# APP_RCM register map
Vendor: Texas Instruments
Peripheral module from a debugger description file (folder xwrl64xx).
Registers are 32-bit, read-write, no defined reset value unless marked. A register's access mark holds for its fields unless they carry their own. Offsets are as the file gives them; lines under a group give offsets from that group; [hi:lo] are bit positions; {n}, {i} and the like mark numbered series; 'fields as' and 'values as' point back to an identical list; <NAME> marks a mode.

## APP_RCM
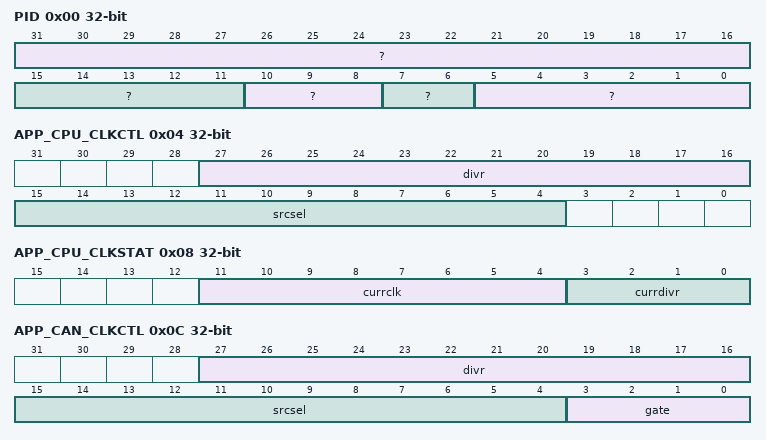
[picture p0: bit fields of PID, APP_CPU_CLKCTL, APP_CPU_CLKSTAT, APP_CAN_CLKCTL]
0x00 PID ro
  [31:16] ?, [15:11] ?, [10:8] ?, [7:6] ?, [5:0] ?
0x04 APP_CPU_CLKCTL
  [27:16] divr — Divide value 0x0 : div1 0x1 : div2 0x2 : div3 . . 0xF = div16 Data should be loaded as multibit. For example: if divider value of '0x8' should be selected then '0x888' should be configured to the register.
  [15:4] srcsel — Select the source clock: 0x0 : OSC_CLK 0x1 : SLOW_CLK 0x2 : MDLL_CLK 0x3 : FAST_CLK 0x4 : SLOW_CLK 0x5 : SLOW_CLK 0x6 : SLOW_CLK 0x7 : SLOW_CLK For other values if the lower 3 bits matches with above, corresponding clock is selected. Data should be loaded as multibit. For example: if Clock source 0x5 should be selected then 0x555 should be configured to the register.
0x08 APP_CPU_CLKSTAT ro
  [11:4] currclk — Current Clock selected by GCM Clock Mux 0x1 : XTALCLK 0x2 : XTALCLKX2 0x4 : MDLL 0x8 : APLL/DPLL 0x10 : RCCLK
  [3:0] currdivr — Gives the current divr setting used by the clock divider.
0x0C APP_CAN_CLKCTL
  [27:16] divr — Divide value 0x0 : div1 0x1 : div2 0x2 : div3 . . 0xF = div16 Data should be loaded as multibit. For example: if divider value of '0x8' should be selected then '0x888' should be configured to the register.
  [15:4] srcsel — 0x0 : OSC_CLK 0x1 : OSC_CLKX2 0x2 : MDLL_CLK 0x3 : FAST_CLK 0x4 : SLOW_CLK 0x5 : SLOW_CLK 0x6 : SLOW_CLK 0x7 : SLOW_CLKFor other values if the lower 3 bits matches with above, corresponding clock is selected. Data should be loaded as multibit. For example: if Clock source 0x5 should be selected then 0x555 should be configured to the register.
  [3:0] gate — 0x0 : Enable the Clock 0x7 : Gate the clock
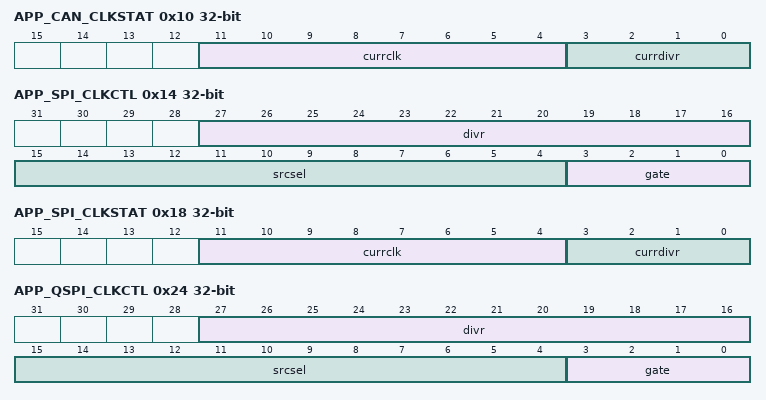
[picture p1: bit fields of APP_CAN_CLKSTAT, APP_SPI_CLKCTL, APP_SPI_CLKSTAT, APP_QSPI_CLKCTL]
0x10 APP_CAN_CLKSTAT ro
  fields as APP_CPU_CLKSTAT
0x14 APP_SPI_CLKCTL
  [27:16] divr — Divide value 0x0 : div1 0x1 : div2 0x2 : div3 . . 0xF = div16 Data should be loaded as multibit. For example: if divider value of '0x8' should be selected then '0x888' should be configured to the register.
  [15:4] srcsel — 0x0 : OSC_CLK 0x1 : OSC_CLKX2 0x2 : MDLL_CLK 0x3 : FAST_CLK 0x4 : SLOW_CLK 0x5 : SLOW_CLK 0x6 : SLOW_CLK 0x7 : SLOW_CLK For other values if the lower 3 bits matches with above, corresponding clock is selected. Data should be loaded as multibit. For example: if Clock source 0x5 should be selected then 0x555 should be configured to the register.
  [3:0] gate — 0x0 : Enable the Clock 0x7 : Gate the clock
0x18 APP_SPI_CLKSTAT ro
  fields as APP_CPU_CLKSTAT
0x1C APP_SPI_BUSIF_CLKCTL
  [11:0] divr — Divide value 0x0 : div1 0x1 : div2 0x2 : div3 . . 0xF = div16 Data should be loaded as multibit. For example: if divider value of '0x8' should be selected then '0x888' should be configured to the register.
0x20 APP_SPI_BUSIF_CLKSTAT ro
  [3:0] currdivr — Gives the current divr setting used by the clock divider.
0x24 APP_QSPI_CLKCTL
  fields as APP_SPI_CLKCTL
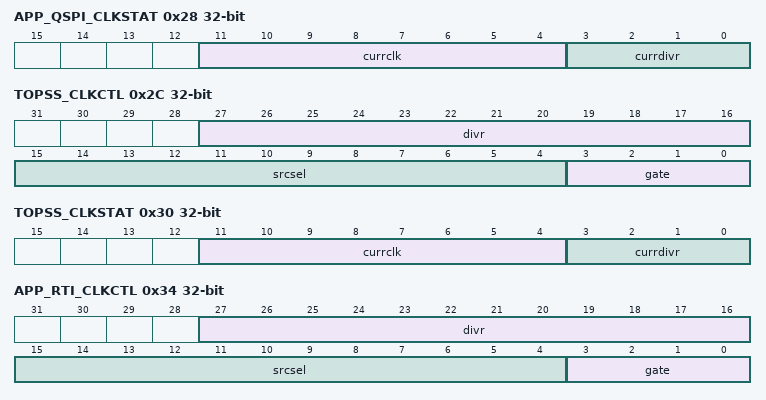
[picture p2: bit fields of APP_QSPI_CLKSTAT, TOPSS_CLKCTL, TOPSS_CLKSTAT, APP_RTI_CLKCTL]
0x28 APP_QSPI_CLKSTAT ro
  fields as APP_CPU_CLKSTAT
0x2C TOPSS_CLKCTL
  [27:16] divr — Divide value 0x0 : div1 0x1 : div2 0x2 : div3 . . 0xF = div16 Data should be loaded as multibit. For example: if divider value of '0x8' should be selected then '0x888' should be configured to the register.
  [15:4] srcsel — 0x0 : OSC_CLK 0x1 : SLOW_CLK 0x2 : MDLL 0x3 : FAST_CLK 0x4 : SLOW_CLK For other values if the lower 3 bits matches with above, corresponding clock is selected. Data should be loaded as multibit. For example: if Clock source 0x5 should be selected then 0x555 should be configured to the register.
  [3:0] gate — 0x0 : Enable the Clock 0x7 : Gate the clock
0x30 TOPSS_CLKSTAT ro
  fields as APP_CPU_CLKSTAT
0x34 APP_RTI_CLKCTL
  [27:16] divr — Divide value 0x0 : div1 0x1 : div2 0x2 : div3 . . 0xF = div16 Data should be loaded as multibit. For example: if divider value of '0x8' should be selected then '0x888' should be configured to the register.
  [15:4] srcsel — 0x0 : OSC_CLK 0x1 : XREF_IN 0x2 : OSC_CLK (Ungated OSC_CLK for RTI in Sleep mode) 0x3 : SLOW_CLK 0x4 : SLOW_CLK 0x5 : SLOW_CLK 0x6 : SLOW_CLK 0x7 : SLOW_CLK For other values if the lower 3 bits matches with above, corresponding clock is selected. Data should be loaded as multibit. For example: if Clock source 0x5 should be selected then 0x555 should be configured to the register.
  [3:0] gate — 0x0 : Enable the Clock 0x7 : Gate the clock
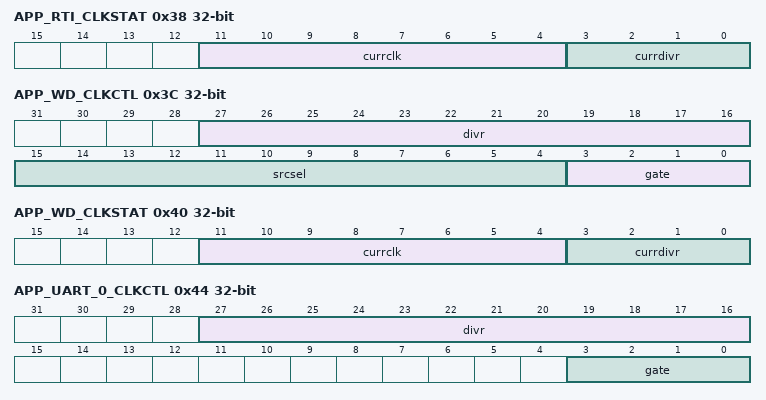
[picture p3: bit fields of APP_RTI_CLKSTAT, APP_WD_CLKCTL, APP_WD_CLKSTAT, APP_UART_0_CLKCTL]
0x38 APP_RTI_CLKSTAT ro
  fields as APP_CPU_CLKSTAT
0x3C APP_WD_CLKCTL
  [27:16] divr — Divide value 0x0 : div1 0x1 : div2 0x2 : div3 . . 0xF = div16 Data should be loaded as multibit. For example: if divider value of '0x8' should be selected then '0x888' should be configured to the register.
  [15:4] srcsel — 0x0 : OSC_CLK 0x1 : XREF_IN 0x2 : OSC_CLK 0x3 : SLOW_CLK 0x4 : SLOW_CLK 0x5 : SLOW_CLK 0x6 : SLOW_CLK 0x7 : SLOW_CLK For other values if the lower 3 bits matches with above, corresponding clock is selected. Data should be loaded as multibit. For example: if Clock source 0x5 should be selected then 0x555 should be configured to the register.
  [3:0] gate — 0x0 : Enable the Clock 0x7 : Gate the clock
0x40 APP_WD_CLKSTAT ro
  fields as APP_CPU_CLKSTAT
0x44 APP_UART_0_CLKCTL
  [27:16] divr — Divide value 0x0 : div1 0x1 : div2 0x2 : div3 . . 0xF = div16 Data should be loaded as multibit. For example: if divider value of '0x8' should be selected then '0x888' should be configured to the register.
  [3:0] gate — 0x0 : Enable the Clock 0x7 : Gate the clock
0x48 APP_UART_0_CLKSTAT ro
  fields as APP_SPI_BUSIF_CLKSTAT
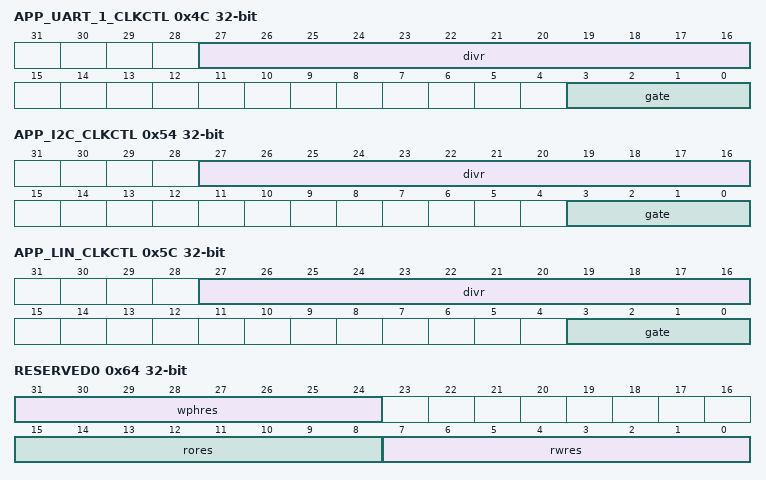
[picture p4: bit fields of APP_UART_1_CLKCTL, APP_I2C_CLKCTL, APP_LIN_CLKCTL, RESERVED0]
0x4C APP_UART_1_CLKCTL
  fields as APP_UART_0_CLKCTL
0x50 APP_UART_1_CLKSTAT ro
  fields as APP_SPI_BUSIF_CLKSTAT
0x54 APP_I2C_CLKCTL
  fields as APP_UART_0_CLKCTL
0x58 APP_I2C_CLKSTAT ro
  fields as APP_SPI_BUSIF_CLKSTAT
0x5C APP_LIN_CLKCTL
  fields as APP_UART_0_CLKCTL
0x60 APP_LIN_CLKSTAT ro
  fields as APP_SPI_BUSIF_CLKSTAT
0x64 RESERVED0 access per field
  [31:24] wphres rw — Reserved
  [15:8] rores ro — Reserved
  [7:0] rwres rw — Bit 2:0 - Software reset for hwass cba3to2 and m64top32 bridge instances in appss. (reset value - 0) Bit 5:3 - Software reset for fecss p2p async bridge instance in appss. (reset value - 0) 0x0 : Release the reset 0x7 : Assert the reset Bit 31:6 - Reserved
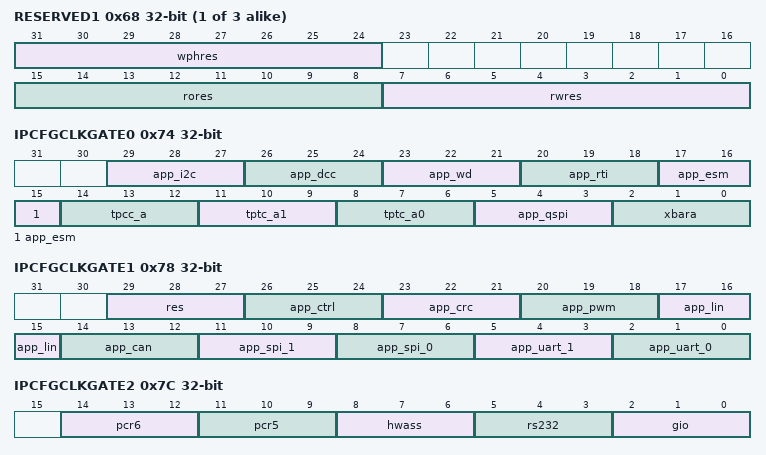
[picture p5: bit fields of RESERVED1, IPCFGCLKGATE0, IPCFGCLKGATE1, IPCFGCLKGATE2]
{0x64+4i} RESERVED{i} access per field (i=1..3)
  [31:24] wphres rw — Reserved
  [15:8] rores ro — Reserved
  [7:0] rwres rw — Reserved
0x74 IPCFGCLKGATE0
  [29:27] app_i2c — 0x0 : Enable the Clock 0x7 : Gate the clock
  [26:24] app_dcc — 0x0 : Enable the Clock 0x7 : Gate the clock
  [23:21] app_wd — 0x0 : Enable the Clock 0x7 : Gate the clock
  [20:18] app_rti — 0x0 : Enable the Clock 0x7 : Gate the clock
  [17:15] app_esm — 0x0 : Enable the Clock 0x7 : Gate the clock
  [14:12] tpcc_a — 0x0 : Enable the Clock 0x7 : Gate the clock
  [11:9] tptc_a1 — 0x0 : Enable the Clock 0x7 : Gate the clock
  [8:6] tptc_a0 — 0x0 : Enable the Clock 0x7 : Gate the clock
  [5:3] app_qspi — 0x0 : Enable the Clock 0x7 : Gate the clock
  [2:0] xbara — Reserved Setting this bit does not cause any affect to any logic
0x78 IPCFGCLKGATE1
  [29:27] res — 0x0 : Enable the Clock 0x7 : Gate the clock
  [26:24] app_ctrl — 0x0 : Enable the Clock 0x7 : Gate the clock
  [23:21] app_crc — 0x0 : Enable the Clock 0x7 : Gate the clock
  [20:18] app_pwm — 0x0 : Enable the Clock 0x7 : Gate the clock
  [17:15] app_lin — 0x0 : Enable the Clock 0x7 : Gate the clock
  [14:12] app_can — 0x0 : Enable the Clock 0x7 : Gate the clock
  [11:9] app_spi_1 — 0x0 : Enable the Clock 0x7 : Gate the clock
  [8:6] app_spi_0 — 0x0 : Enable the Clock 0x7 : Gate the clock
  [5:3] app_uart_1 — 0x0 : Enable the Clock 0x7 : Gate the clock
  [2:0] app_uart_0 — 0x0 : Enable the Clock 0x7 : Gate the clock
0x7C IPCFGCLKGATE2
  [14:12] pcr6 — 0x0 : Enable the Clock 0x7 : Gate the clock
  [11:9] pcr5 — 0x0 : Enable the Clock 0x7 : Gate the clock
  [8:6] hwass — 0x0 : Enable the Clock 0x7 : Gate the clock
  [5:3] rs232 — 0x0 : Enable the Clock 0x7 : Gate the clock
  [2:0] gio — 0x0 : Enable the Clock 0x7 : Gate the clock
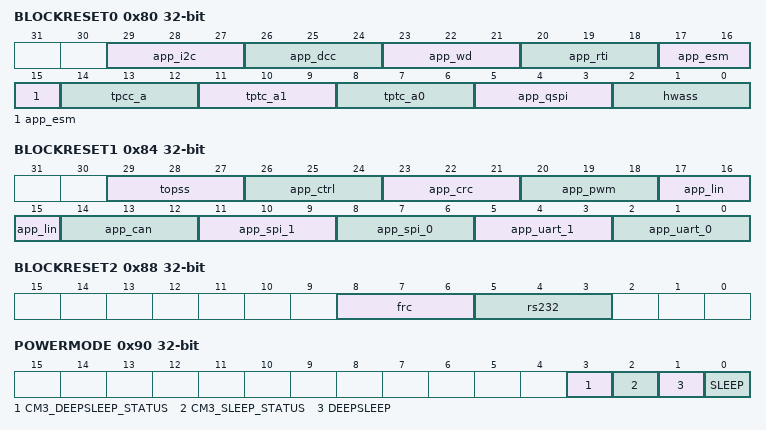
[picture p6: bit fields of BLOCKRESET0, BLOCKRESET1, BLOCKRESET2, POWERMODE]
0x80 BLOCKRESET0
  [29:27] app_i2c — 0x0 : Release the reset 0x7 : Assert the reset
  [26:24] app_dcc — 0x0 : Release the reset 0x7 : Assert the reset
  [23:21] app_wd — 0x0 : Release the reset 0x7 : Assert the reset
  [20:18] app_rti — 0x0 : Release the reset 0x7 : Assert the reset
  [17:15] app_esm — 0x0 : Release the reset 0x7 : Assert the reset
  [14:12] tpcc_a — 0x0 : Release the reset 0x7 : Assert the reset
  [11:9] tptc_a1 — 0x0 : Release the reset 0x7 : Assert the reset
  [8:6] tptc_a0 — 0x0 : Release the reset 0x7 : Assert the reset
  [5:3] app_qspi — 0x0 : Release the reset 0x7 : Assert the reset
  [2:0] hwass — 0x0 : Release the reset 0x7 : Assert the reset
0x84 BLOCKRESET1
  [29:27] topss — 0x0 : Release the reset 0x7 : Assert the reset
  [26:24] app_ctrl — 0x0 : Release the reset 0x7 : Assert the reset
  [23:21] app_crc — 0x0 : Release the reset 0x7 : Assert the reset
  [20:18] app_pwm — 0x0 : Release the reset 0x7 : Assert the reset
  [17:15] app_lin — 0x0 : Release the reset 0x7 : Assert the reset
  [14:12] app_can — 0x0 : Release the reset 0x7 : Assert the reset
  [11:9] app_spi_1 — 0x0 : Release the reset 0x7 : Assert the reset
  [8:6] app_spi_0 — 0x0 : Release the reset 0x7 : Assert the reset
  [5:3] app_uart_1 — 0x0 : Release the reset 0x7 : Assert the reset
  [2:0] app_uart_0 — 0x0 : Release the reset 0x7 : Assert the reset
0x88 BLOCKRESET2
  [8:6] frc — 0x0 : Release the reset 0x7 : Assert the reset
  [5:3] rs232 — 0x0 : Release the reset 0x7 : Assert the reset
0x8C PLATFORM_SIGNATURE
  [31:0] signature — Platform signature to identify the platform
0x90 POWERMODE access per field
  [3] CM3_DEEPSLEEP_STATUS ro — CM3 Core Deep Sleep Status
  [2] CM3_SLEEP_STATUS ro — CM3 Core Sleep Status
  [1] DEEPSLEEP rw — 0x0 : CM4 CORE DEEP SLEEP 0x1 : DEVICE DEEP SLEEP
  [0] SLEEP rw — 0x0 : CM4 CORE SLEEP 0x1 : DEVICE SLEEP
0x94 RST_WFICHECK
  [2:0] cpu — Writing '000' will disable check for WFI before local reset assertion of app cpu
0x98 RST_ASSERTDLY
  [7:0] common — Value decides number of cycles reset should be asserted for cpu
0x9C RST2ASSERTDLY
  [15:8] cpu — Value decides number of cycles to be held before asserting reset for app cpu
0xA0 RST_FSM_TRIG
  [2:0] cpu — FSM Reset Trigger
0xA4 RST_CAUSE ro
  [7:0] common — Reset cause register for APP CPU 0x00 - All cleared 0x01 - Power On Reset (PoR) 0x02 - Subsystem Reset (Combination of Warm Reset initiated from PRCM using LPRADAR:TOP_PRCM:RST_APP_PD_SOFT_RESET and PoR reset) 0x04 - STC RESET 0x08 - Reserved 0x10 - CPU Only Reset triggered by writing to LPRADAR:APP_RCM:RST_FSM_TRIG<RST_FSM_TRIG_CPU> (self triggered CPU reset during MEMSWAP/ECLIPSE mode to wait for WFI to assert the reset to CPU) 0x20 - Core Reset initiated from PRCM using LPRADAR:TOP_PRCM:RST_SOFT_APP_CORE_SYSRESET_REQ (reset CPU unconditionally - by debugger) or LPRADAR:TOP_PRCM:APP_CORE_SYSRESET_PARAM_WAKEUP_OUT_STATE 0x40 - Reserved
0xA8 RST_CAUSE_CLR
  [2:0] cpu — Writing '111' will clear the RST_CAUSE register
0xAC XTALCLK_CLK_GATE
  [2:0] XTALCLK_CLK_GATE — RESERVED
0xB0 XTALCLKX2_CLK_GATE
  [2:0] XTALCLKX2_CLK_GATE — Writing 3'b111 will gate the XTALX2 clock.Writing 3'b000 will ungate the clock.
0xB4 APLLDIV2_CLK_GATE
  [2:0] APLLDIV2_CLK_GATE — Writing 3'b111 will gate the APLL/2clock to EDCC.Writing 3'b000 will ungate the clock.
0xB8 DFT_APPSS_LSTC_CLK_GATE
  [2:0] DFT_APPSS_LSTC_CLK_GATE — Writing 3'b111 will gate the clock to LSTC.Writing 3'b000 will ungate the clock.
0xBC DFT_APPSS_LSTC_VBUSP_CLK_GATE
  [2:0] enable — 3'b000 : Gate clock to LSTC VBUSP 3'b111 : Ungate Clock to LSTC VBUSP
0xC0 APP_ROM_CLOCK_GATE
  [2:0] enable — 3'b000 : Ungate clock to APP ROM 3'b111 : Gate Clock to APP ROM
0xC4 APP_RAM1_CLOCK_GATE
  [2:0] enable — 3'b000 : Ungate clock to APP RAM1 3'b111 : Gate Clock to APP_RAM1
0xC8 APP_RAM2_CLOCK_GATE
  [2:0] enable — 3'b000 : Ungate clock to APP RAM2 3'b111 : Gate Clock to APP RAM2
0xCC APP_RAM3_CLOCK_GATE
  [2:0] enable — 3'b000 : Ungate clock to APP RAM3 3'b111 : Gate Clock to APP RAM3
0xD0 CFG_XBARA_DYNAMIC_CG
  [2:0] enable — Enable APPSS crossbar dynamic clock gating. 1 - Dynamic clock gating feature is enabled. When the feature is enabed, the CM4 should monitor for any possible pending transactions from various masters like DMA/NWA and if no transaction is expected to be iniated by the masters, the CM4 executes WFI. On ssertion of WFI signal, the clock to crossbar is gated. The clock is automatically ungated under two conditions (i) when the WFI signal is deasserted by any interrupted (ii) when any of the APPSS TPCC triggers are asserted. Instead of WFI, cfg_xbara_set_dynamic_cg also can be used to start the clock gating. 0 - Dynamic clock gating feature is disabled. The clock to APPSS crossbar is not gated dynamically. The clock to APPSS crossbar is gated/ungated as per device ice level power states.
0xD4 CFG_TPTC1_DYNAMIC_CG
  [2:0] enable — Enable APPSS TPTC1 crossbar dynamic clock gating. 1 - Dynamic clock gating feature is enabled. Same behaviour as cfg_xbara_dynamic_cg_en - for both entry to clock gating and exit from clock gating. WFI or cfg_tptc1_set_dynamic_cg 0 - Dynamic clock gating feature is disabled. The clock to APPSS TPTC1 crossbar is not gated dynamically. The clock to APPSS TPTC1 crossbar is gated/ungated as per device ice level power states.
0xD8 CFG_TPTC2_DYNAMIC_CG
  [2:0] enable — Enable APPSS TPTC2 crossbar dynamic clock gating. 1 - Dynamic clock gating feature is enabled. Same behaviour as cfg_xbara_dynamic_cg_en - for both entry to clock gating and exit from clock gating. WFI or cfg_tptc2_set_dynamic_cg 0 - Dynamic clock gating feature is disabled. The clock to APPSS TPTC2 crossbar is not gated dynamically. The clock to APPSS TPTC2 crossbar is gated/ungated as per device ice level power states
0xDC CFG_XBARA_SET_DYNAMIC_CG
  [0] set — Start APPSS crossbar dynamic clock gating. This is used instead of WFI. 1 - Start the clock gating. In order to start again, write 0 followed by 1. Rise edge is detected internally, to start the clock gating. 0 - Clock is ungated. Fall edge is detected internally to ungate the clock.
0xE0 CFG_TPTC1_SET_DYNAMIC_CG
  [0] set — Start APPSS tptc1 dynamic clock gating. This is used instead of WFI. 1 - Start the clock gating. In order to start again, write 0 followed by 1. Rise edge is detected internally, to start the clock gating. 0 - Clock is ungated. Fall edge is detected internally to ungate the clock.
0xE4 CFG_TPTC2_SET_DYNAMIC_CG
  [0] set — Start APPSS tptc2 dynamic clock gating. This is used instead of WFI. 1 - Start the clock gating. In order to start again, write 0 followed by 1. Rise edge is detected internally, to start the clock gating. 0 - Clock is ungated. Fall edge is detected internally to ungate the clock.
0xE8 CM4_FORCE_HCLK_GATE
  [2:0] enable — 3'b000 - CM4 HCLK is ungated 3'b111 - CM4 HCLK is gated
0xEC LIN_SCI_DIV
  [7:0] val — ICG Based Divider for LIN
0xF0 APP_LSTC_EN
  [0] enable — Enable vbusp_req and clk_en for app lstc
0x1008 LOCK0_KICK0 — - KICK0 component
  [31:0] ?
0x100C LOCK0_KICK1 — - KICK1 component
  [31:0] ?
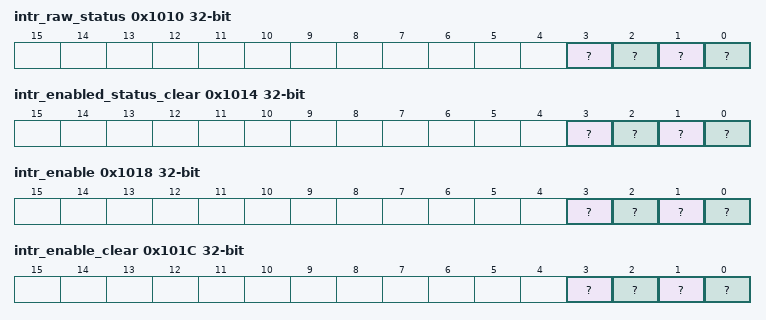
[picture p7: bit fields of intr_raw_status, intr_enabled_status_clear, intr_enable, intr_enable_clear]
0x1010 intr_raw_status — Interrupt Raw Status/Set Register
  [3] ? — Proxy0 access violation error. Raw status is read. Write a 1 to set the status. Writing a 0 has no effect.
  [2] ? — Kick access violation error. Raw status is read. Write a 1 to set the status. Writing a 0 has no effect.
  [1] ? — Addressing violation error. Raw status is read. Write a 1 to set the status. Writing a 0 has no effect.
  [0] ? — Protection violation error. Raw status is read. Write a 1 to set the status. Writing a 0 has no effect.
0x1014 intr_enabled_status_clear — Interrupt Enabled Status/Clear register
  [3] ? — Proxy0 access violation error. Enabled status is read. Write a 1 to clear the status. Writing a 0 has no effect.
  [2] ? — Kick access violation error. Enabled status is read. Write a 1 to clear the status. Writing a 0 has no effect.
  [1] ? — Addressing violation error. Enabled status is read. Write a 1 to clear the status. Writing a 0 has no effect.
  [0] ? — Protection violation error. Enabled status is read. Write a 1 to clear the status. Writing a 0 has no effect.
0x1018 intr_enable — Interrupt Enable register
  [3] ? — Proxy0 access violation error enable. Write a 1 to set the enable. Writing a 0 has no effect.
  [2] ? — Kick access violation error enable. Write a 1 to set the enable. Writing a 0 has no effect.
  [1] ? — Addressing violation error enable. Write a 1 to set the enable. Writing a 0 has no effect.
  [0] ? — Protection violation error enable. Write a 1 to set the enable. Writing a 0 has no effect.
0x101C intr_enable_clear — Interrupt Enable Clear register
  [3] ? — Proxy0 access violation error enable clear. Write a 1 to clear the enable. Writing a 0 has no effect.
  [2] ? — Kick access violation error enable clear. Write a 1 to clear the enable. Writing a 0 has no effect.
  [1] ? — Addressing violation error enable clear. Write a 1 to clear the enable. Writing a 0 has no effect.
  [0] ? — Protection violation error enable clear. Write a 1 to clear the enable. Writing a 0 has no effect.
0x1020 eoi
  [7:0] ? — EOI vector value. Write this with interrupt distribution value in the chip.
0x1024 fault_address ro
  [31:0] ? — Fault Address.
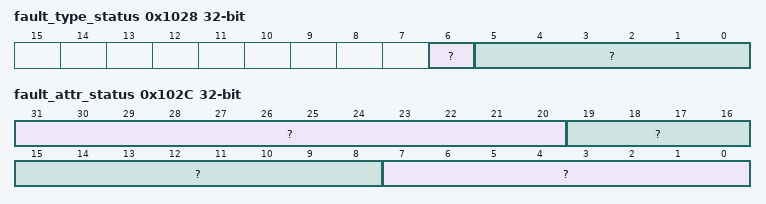
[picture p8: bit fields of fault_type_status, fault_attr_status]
0x1028 fault_type_status ro
  [6] ? — Non-secure access.
  [5:0] ? — Fault Type 10_0000 = Supervisor read fault - priv = 1 dir = 1 dtype != 1 01_0000 = Supervisor write fault - priv = 1 dir = 0 00_1000 = Supervisor execute fault - priv = 1 dir = 1 dtype = 1 00_0100 = User read fault - priv = 0 dir = 1 dtype = 1 00_0010 = User write fault - priv = 0 dir = 0 00_0001 = User execute fault - priv = 0 dir = 1 dtype = 1 00_0000 = No fault
0x102C fault_attr_status ro — Fault Attribute Status register
  [31:20] ? — XID.
  [19:8] ? — Route ID.
  [7:0] ? — Privilege ID.
0x1030 fault_clear wo
  [0] ? — Fault clear. Writing a 1 clears the current fault. Writing a 0 has no effect.
